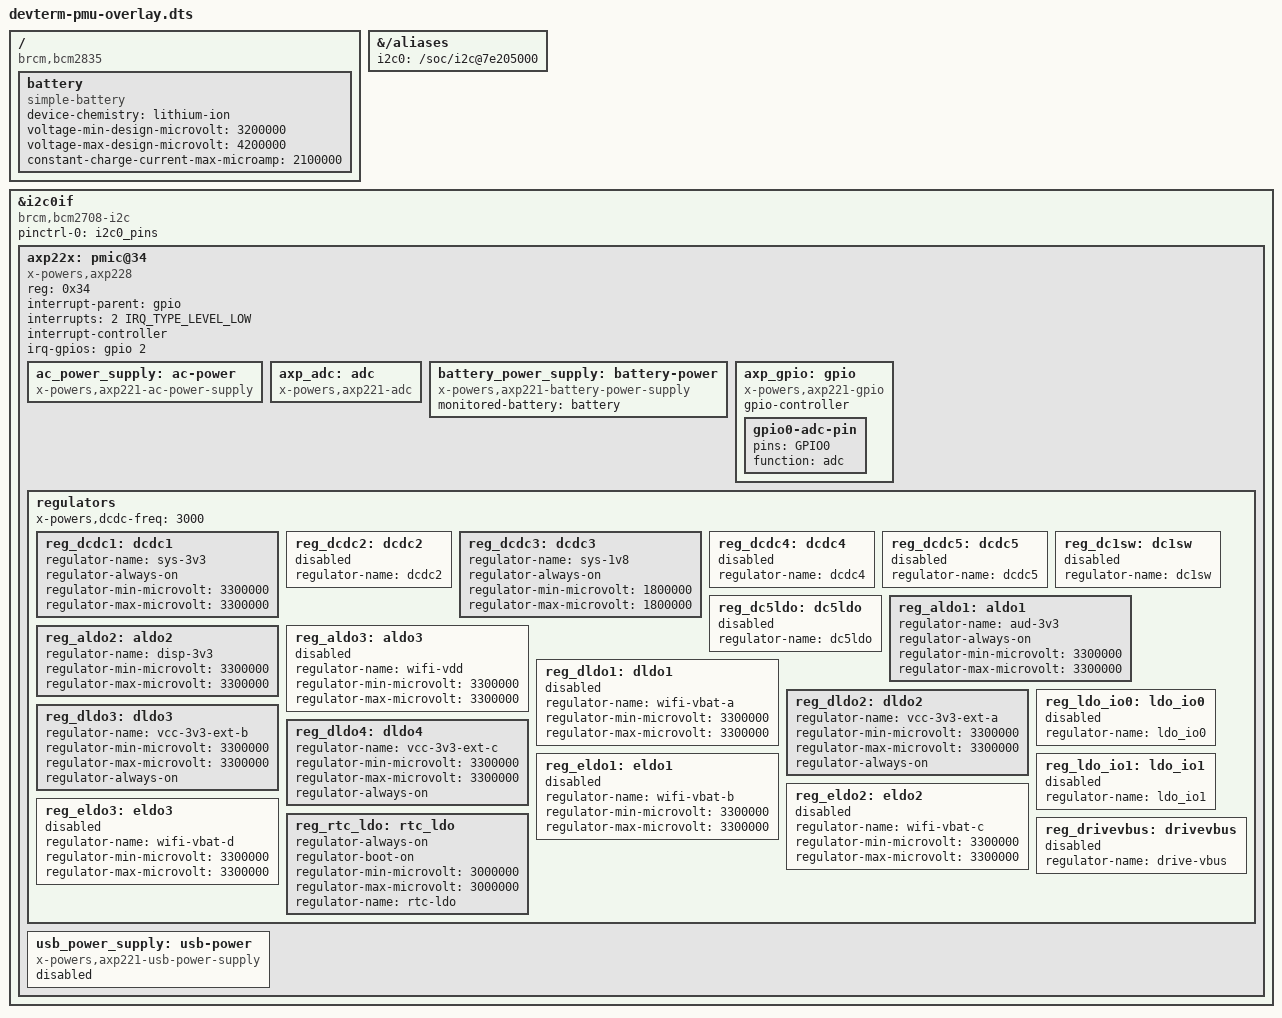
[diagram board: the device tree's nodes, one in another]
/dts-v1/;
/plugin/;

#include <dt-bindings/gpio/gpio.h>
#include <dt-bindings/interrupt-controller/irq.h>

/ {
	compatible = "brcm,bcm2835";

	fragment@0 {
		target-path = "/";
		__overlay__  {
			battery: battery {
				compatible = "simple-battery";
				device-chemistry = "lithium-ion";
				voltage-min-design-microvolt = <3200000>;
				voltage-max-design-microvolt = <4200000>;
				constant-charge-current-max-microamp = <2100000>;
			};
		};
	};

	fragment@1 {
		target-path = "/aliases";
		__overlay__ {
			i2c0 = "/soc/i2c@7e205000";
		};
	};

	fragment@2 {
		target = <&i2c0if>;
		__overlay__ {
			compatible = "brcm,bcm2708-i2c";
			pinctrl-0 = <&i2c0_pins>;
			pinctrl-names = "default";
			status = "okay";

			axp22x: pmic@34 {
				compatible = "x-powers,axp228", "x-powers,axp221";
				reg = <0x34>;
				interrupt-parent = <&gpio>;
				interrupts = <2 IRQ_TYPE_LEVEL_LOW>;
				interrupt-controller;
				#interrupt-cells = <1>;

				irq-gpios = <&gpio 2 GPIO_ACTIVE_HIGH>;

				ac_power_supply: ac-power {
					compatible = "x-powers,axp221-ac-power-supply";
					status = "okay";
				};

				axp_adc: adc {
					compatible = "x-powers,axp221-adc";
					#io-channel-cells = <1>;
				};

				battery_power_supply: battery-power {
					compatible = "x-powers,axp221-battery-power-supply";
					status = "okay";
					monitored-battery = <&battery>;
				};

				axp_gpio: gpio {
					compatible = "x-powers,axp221-gpio";
					gpio-controller;
					#gpio-cells = <2>;

					gpio0-adc-pin {
						pins = "GPIO0";
						function = "adc";
					};
				};

				regulators {
					/* Default work frequency for buck regulators */
					x-powers,dcdc-freq = <3000>;

					reg_dcdc1: dcdc1 {
						regulator-name = "sys-3v3";
						regulator-always-on;
						regulator-min-microvolt = <3300000>;
						regulator-max-microvolt = <3300000>;
					};

					reg_dcdc2: dcdc2 {
						regulator-name = "dcdc2";
						status = "disabled";
					};

					reg_dcdc3: dcdc3 {
						regulator-name = "sys-1v8";
						regulator-always-on;
						regulator-min-microvolt = <1800000>;
						regulator-max-microvolt = <1800000>;
					};

					reg_dcdc4: dcdc4 {
						regulator-name = "dcdc4";
						status = "disabled";
					};

					reg_dcdc5: dcdc5 {
						regulator-name = "dcdc5";
						status = "disabled";
					};

					reg_dc1sw: dc1sw {
						regulator-name = "dc1sw";
						status = "disabled";
					};

					reg_dc5ldo: dc5ldo {
						regulator-name = "dc5ldo";
						status = "disabled";
					};

					reg_aldo1: aldo1 {
						regulator-name = "aud-3v3";
						regulator-always-on;
						regulator-min-microvolt = <3300000>;
						regulator-max-microvolt = <3300000>;
					};

					reg_aldo2: aldo2 {
						regulator-name = "disp-3v3";
						regulator-min-microvolt = <3300000>;
						regulator-max-microvolt = <3300000>;
					};

					reg_aldo3: aldo3 {
						regulator-name = "wifi-vdd";
						regulator-min-microvolt = <3300000>;
						regulator-max-microvolt = <3300000>;
						status = "disabled";
					};

					reg_dldo1: dldo1 {
						regulator-name = "wifi-vbat-a";
						regulator-min-microvolt = <3300000>;
						regulator-max-microvolt = <3300000>;
						status = "disabled";
					};

					reg_dldo2: dldo2 {
						regulator-name = "vcc-3v3-ext-a";
						regulator-min-microvolt = <3300000>;
						regulator-max-microvolt = <3300000>;
						regulator-always-on;
					};

					reg_dldo3: dldo3 {
						regulator-name = "vcc-3v3-ext-b";
						regulator-min-microvolt = <3300000>;
						regulator-max-microvolt = <3300000>;
						regulator-always-on;
					};

					reg_dldo4: dldo4 {
						regulator-name = "vcc-3v3-ext-c";
						regulator-min-microvolt = <3300000>;
						regulator-max-microvolt = <3300000>;
						regulator-always-on;
					};

					reg_eldo1: eldo1 {
						regulator-name = "wifi-vbat-b";
						regulator-min-microvolt = <3300000>;
						regulator-max-microvolt = <3300000>;
						status = "disabled";
					};

					reg_eldo2: eldo2 {
						regulator-name = "wifi-vbat-c";
						regulator-min-microvolt = <3300000>;
						regulator-max-microvolt = <3300000>;
						status = "disabled";
					};

					reg_eldo3: eldo3 {
						regulator-name = "wifi-vbat-d";
						regulator-min-microvolt = <3300000>;
						regulator-max-microvolt = <3300000>;
						status = "disabled";
					};

					reg_ldo_io0: ldo_io0 {
						regulator-name = "ldo_io0";
						status = "disabled";
					};

					reg_ldo_io1: ldo_io1 {
						regulator-name = "ldo_io1";
						status = "disabled";
					};

					reg_rtc_ldo: rtc_ldo {
						/* RTC_LDO is a fixed, always-on regulator */
						regulator-always-on;
						regulator-boot-on;
						regulator-min-microvolt = <3000000>;
						regulator-max-microvolt = <3000000>;
						regulator-name = "rtc-ldo";
					};

					reg_drivevbus: drivevbus {
						regulator-name = "drive-vbus";
						status = "disabled";
					};
				};

				usb_power_supply: usb-power {
					compatible = "x-powers,axp221-usb-power-supply";
					status = "disabled";
				};
			};
		};
	};

	__exports__ {
		/* Export the various regulators */
		reg_dcdc1; /* sys-3v3 */
		reg_dcdc3; /* sys-1v8 */
		reg_aldo1; /* aud-3v3 */
		reg_aldo2; /* disp-3v3 */
		reg_aldo3; /* wifi-vdd */
		reg_dldo2; /* vcc-3v3-ext-a */
		reg_dldo3; /* vcc-3v3-ext-b */
		reg_dldo4; /* vcc-3v3-ext-c */
		reg_dldo1; /* wifi-vbat-a */
		reg_eldo1; /* wifi-vbat-b */
		reg_eldo2; /* wifi-vbat-c */
		reg_eldo3; /* wifi-vbat-d */
		reg_rtc_ldo; /* rtc-ldo */
		/* and the power supplies */
		ac_power_supply;
		battery_power_supply;
		usb_power_supply;
		/* and the ADC/GPIO */
		axp_adc;
		axp_gpio;
	};
};
